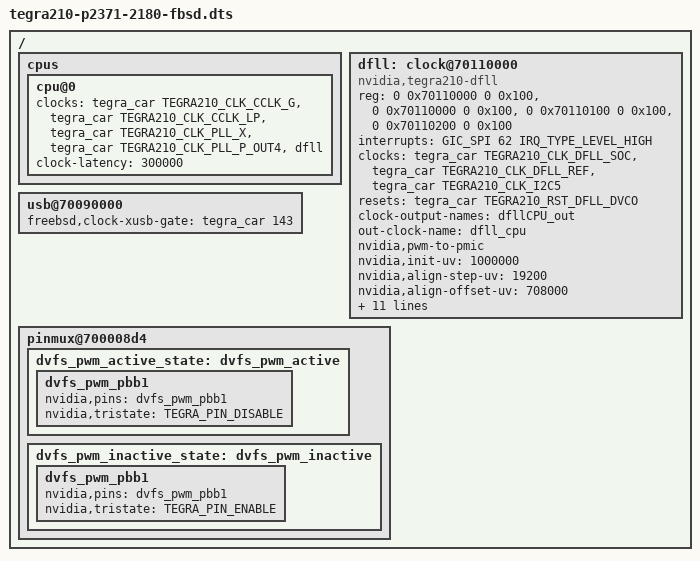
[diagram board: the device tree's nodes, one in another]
#include "nvidia/tegra210-p2371-2180.dts"

/* tegra210.dtsi patches */
#include <dt-bindings/reset/tegra210-car.h>
/ {
	cpus {
		cpu@0 {
			clocks = <&tegra_car TEGRA210_CLK_CCLK_G>,
				 <&tegra_car TEGRA210_CLK_CCLK_LP>,
				 <&tegra_car TEGRA210_CLK_PLL_X>,
				 <&tegra_car TEGRA210_CLK_PLL_P_OUT4>,
				 <&dfll>;
			clock-names = "cpu_g", "cpu_lp", "pll_x", "pll_p", "dfll";
			clock-latency = <300000>;
		};
	};

	dfll: clock@70110000 {
		compatible = "nvidia,tegra210-dfll";
		reg = <0 0x70110000 0 0x100>, /* DFLL control */
		      <0 0x70110000 0 0x100>, /* I2C output control */
		      <0 0x70110100 0 0x100>, /* Integrated I2C controller */
		      <0 0x70110200 0 0x100>; /* Look-up table RAM */
		interrupts = <GIC_SPI 62 IRQ_TYPE_LEVEL_HIGH>;
		clocks = <&tegra_car TEGRA210_CLK_DFLL_SOC>,
		         <&tegra_car TEGRA210_CLK_DFLL_REF>,
		         <&tegra_car TEGRA210_CLK_I2C5>;
		clock-names = "soc", "ref", "i2c";
		resets = <&tegra_car TEGRA210_RST_DFLL_DVCO>;
		reset-names = "dvco";
		#clock-cells = <0>;
		clock-output-names = "dfllCPU_out";
		out-clock-name = "dfll_cpu";
		status = "disabled";
	};


};

/* tegra210-p2180.dtsi patches */
/ {
	clock@70110000 {
		status = "okay";
		nvidia,pwm-to-pmic;
		nvidia,init-uv = <1000000>;
		nvidia,align-step-uv = <19200>; /* 19.2mv */
		nvidia,align-offset-uv = <708000>; /* 708mv */
		nvidia,sample-rate = <25000>;
		nvidia,droop-ctrl = <0x00000f00>;
		nvidia,force-mode = <1>;
		nvidia,cf = <6>;
		nvidia,ci = <0>;
		nvidia,cg = <2>;
		nvidia,idle-override;
		nvidia,one-shot-calibrate;
		nvidia,pwm-period = <2500>; /* 2.5us */
		pinctrl-names = "dvfs_pwm_enable", "dvfs_pwm_disable";
		pinctrl-0 = <&dvfs_pwm_active_state>;
		pinctrl-1 = <&dvfs_pwm_inactive_state>;
	};
}
	
/* tegra210-p2597.dtsi patches */
/ {
	usb@70090000 {
		freebsd,clock-xusb-gate = <&tegra_car 143>;
	};
	
	pinmux@700008d4 {
		dvfs_pwm_active_state: dvfs_pwm_active {
			dvfs_pwm_pbb1 {
				nvidia,pins = "dvfs_pwm_pbb1";
				nvidia,tristate = <TEGRA_PIN_DISABLE>;
			};
		};
		dvfs_pwm_inactive_state: dvfs_pwm_inactive {
			dvfs_pwm_pbb1 {
				nvidia,pins = "dvfs_pwm_pbb1";
				nvidia,tristate = <TEGRA_PIN_ENABLE>;
			};
		};
	}
}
